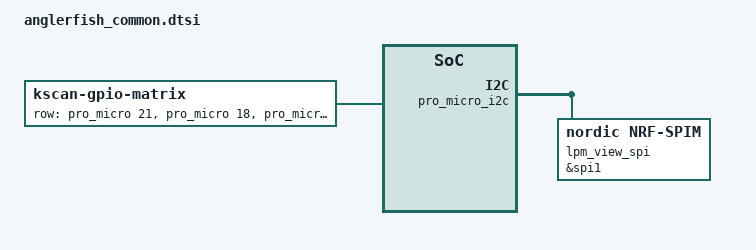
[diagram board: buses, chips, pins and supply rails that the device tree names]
#include <dt-bindings/zmk/matrix_transform.h>

/ {
    chosen {
		zmk,kscan = &kscan0;
		zmk,matrix_transform = &default_transform;
    };

    kscan0: kscan {
        compatible = "zmk,kscan-gpio-matrix";
        label = "KSCAN";
        diode-direction = "col2row";
		row-gpios
			= <&pro_micro 21 (GPIO_ACTIVE_HIGH | GPIO_PULL_DOWN)>
			, <&pro_micro 18 (GPIO_ACTIVE_HIGH | GPIO_PULL_DOWN)>
			, <&pro_micro 5 (GPIO_ACTIVE_HIGH | GPIO_PULL_DOWN)>
			, <&pro_micro 4 (GPIO_ACTIVE_HIGH | GPIO_PULL_DOWN)>
            ;
    };

    left_encoder: encoder_left {
		compatible = "alps,ec11";
		label = "LEFT_ENCODER";
		resolution = <4>;
		status = "disabled";
	};

	right_encoder: encoder_right {
		compatible = "alps,ec11";
		label = "RIGHT_ENCODER";
		resolution = <4>;
		status = "disabled";
	};

    sensors {
		compatible = "zmk,keymap-sensors";
		sensors = <&left_encoder &right_encoder>;
	};
};

&pro_micro_i2c {
    status = "okay";

lpm_view_spi: &spi1 {
    compatible = "nordic,nrf-spim";
    pinctrl-0 = <&spi1_default>;
    pinctrl-1 = <&spi1_sleep>;
    pinctrl-names = "default", "sleep";
    cs-gpios = <&gpio0 6 (GPIO_ACTIVE_HIGH | GPIO_PULL_DOWN) >;
};
